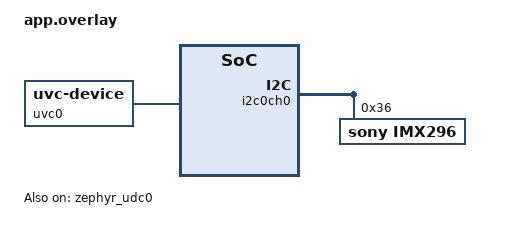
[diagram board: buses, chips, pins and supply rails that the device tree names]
/*
 * Copyright (c) 2025 tinyVision.ai Inc.
 *
 * SPDX-License-Identifier: Apache-2.0
 */

#include <riscv/tinyvision/from_csi0_to_stats0.dtsi>
#include <riscv/tinyvision/from_csi0_to_debayer0.dtsi>
#include <riscv/tinyvision/from_debayer0_to_uvcmanager0.dtsi>

/* USB interfaces */

&zephyr_udc0 {
	num-in-endpoints = <2>;
	num-out-endpoints = <1>;
	status = "okay";

	uvc0: uvc0 {
		compatible = "zephyr,uvc-device";
		interface-name = "tinyCLUNX33-IMX296";
	};
};

&uvcmanager0 {
	usb-endpoint = <0x81>;
};

/* Camera 0 config */

&csi0_ep_in {
	remote-endpoint-label = "imx296_ep_out";
};

&i2c0ch0 {
	imx296@36 {
		compatible = "sony,imx296";
		reg = <0x36>;

		port {
			imx296_ep_out: endpoint {
				remote-endpoint-label = "csi0_ep_in";
			};
		};
	};
};
